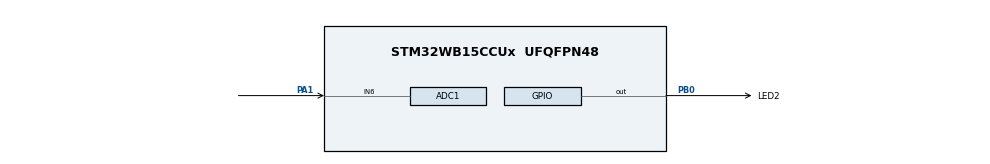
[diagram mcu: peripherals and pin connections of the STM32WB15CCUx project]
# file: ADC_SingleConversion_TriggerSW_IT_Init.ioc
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ADC1.Channel-0\#ChannelRegularConversion=ADC_CHANNEL_6
ADC1.ClockPrescaler=ADC_CLOCK_SYNC_PCLK_DIV4
ADC1.NbrOfConversionFlag=1
ADC1.Overrun=ADC_OVR_DATA_OVERWRITTEN
ADC1.Rank-0\#ChannelRegularConversion=1
ADC1.SamplingTime-0\#ChannelRegularConversion=ADC_SAMPLINGTIME_COMMON_1
ADC1.SamplingTimeCommon1=ADC_SAMPLETIME_79CYCLES_5
ADC1.SelectedChannel=ADC_CHANNEL_6
ADC1.master=1
Mcu.Family=STM32WB
Mcu.Name=STM32WB15CCUx
Mcu.Package=UFQFPN48
NVIC.ADC1_IRQn=true\:0\:0\:false\:false\:false\:true\:true
NVIC.PriorityGroup=NVIC_PRIORITYGROUP_4
PA1.Signal=ADCx_IN6
PB0.GPIO_Label=LED2
PB0.Signal=GPIO_Output
ProjectManager.HeapSize=0x200
ProjectManager.StackSize=0x400
ProjectManager.TargetToolchain=EWARM V8
RCC.AHB2CLKDivider=RCC_SYSCLK_DIV2
RCC.AHBFreq_Value=64000000
RCC.APB1Freq_Value=64000000
RCC.APB1TimFreq_Value=64000000
RCC.APB2Freq_Value=64000000
RCC.APB2TimFreq_Value=64000000
RCC.APB3Freq_Value=16000000
RCC.CortexFreq_Value=64000000
RCC.HCLKFreq_Value=64000000
RCC.HSE_VALUE=8000000
RCC.HSI_VALUE=16000000
RCC.LSE_VALUE=32768
RCC.PLLN=32
RCC.SYSCLKFreq_VALUE=64000000
RCC.SYSCLKSource=RCC_SYSCLKSOURCE_PLLCLK
RCC.VCOOutputFreq_Value=128000000
SH.ADCx_IN6.0=ADC1_IN6,IN6-Single-Ended
board=custom

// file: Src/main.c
/* USER CODE BEGIN Header */
/**
  ******************************************************************************
  * @file    Examples_LL/ADC/ADC_SingleConversion_TriggerSW_IT_Init/Src/main.c
  * @author  MCD Application Team
  * @brief   Use ADC to convert a single channel at each SW start.
  *          Conversion performed using programming model: interrupt
  *          This example is based on the STM32WBxx ADC LL API;
  *          Peripheral initialization done using LL unitary services functions.
  ******************************************************************************
  * @attention
  *
  * <h2><center>&copy; Copyright (c) 2019 STMicroelectronics.
  * All rights reserved.</center></h2>
  *
  * This software component is licensed by ST under BSD 3-Clause license,
  * the "License"; You may not use this file except in compliance with the
  * License. You may obtain a copy of the License at:
  *                        opensource.org/licenses/BSD-3-Clause
  *
  ******************************************************************************
  */
/* USER CODE END Header */
#include "main.h"

/* USER CODE BEGIN PD */

/* Definitions of ADC hardware constraints delays */
/* Note: Only ADC IP HW delays are defined in ADC LL driver driver,           */
/*       not timeout values:                                                  */
/*       Timeout values for ADC operations are dependent to device clock      */
/*       configuration (system clock versus ADC clock),                       */
/*       and therefore must be defined in user application.                   */
/*       Refer to @ref ADC_LL_EC_HW_DELAYS for description of ADC timeout     */
/*       values definition.                                                   */

  /* Timeout values for ADC operations. */
  /* (calibration, enable settling time, disable settling time, ...)          */
  /* Values defined to be higher than worst cases: low clock frequency,       */
  /* maximum prescalers.                                                      */
  /* Note: ADC channel configuration ready (ADC_CHANNEL_CONF_RDY_TIMEOUT_MS)  */
  /*       is added in CubeMx code section.                                   */
  /* Unit: ms                                                                 */
  #define ADC_CALIBRATION_TIMEOUT_MS       (   1UL)
  #define ADC_ENABLE_TIMEOUT_MS            (   1UL)
  #define ADC_DISABLE_TIMEOUT_MS           (   1UL)
  #define ADC_STOP_CONVERSION_TIMEOUT_MS   (   1UL)
  #define ADC_CONVERSION_TIMEOUT_MS        (4000UL)

  /* Delay between ADC end of calibration and ADC enable.                     */
  /* Delay estimation in CPU cycles: Case of ADC enable done                  */
  /* immediately after ADC calibration, ADC clock setting slow                */
  /* (LL_ADC_CLOCK_ASYNC_DIV32). Use a higher delay if ratio                  */
  /* (CPU clock / ADC clock) is above 32.                                     */
  #define ADC_DELAY_CALIB_ENABLE_CPU_CYCLES  (LL_ADC_DELAY_CALIB_ENABLE_ADC_CYCLES * 32)

/* Definitions of environment analog values */
  /* Value of analog reference voltage (Vref+), connected to analog voltage   */
  /* supply Vdda (unit: mV).                                                  */
  #define VDDA_APPLI                       (3300UL)

/* Definitions of data related to this example */
  /* Init variable out of expected ADC conversion data range */
  #define VAR_CONVERTED_DATA_INIT_VALUE    (__LL_ADC_DIGITAL_SCALE(LL_ADC_RESOLUTION_12B) + 1)

/* USER CODE END PD */

/* USER CODE BEGIN PV */

/* Variables for ADC conversion data */
__IO uint16_t uhADCxConvertedData = VAR_CONVERTED_DATA_INIT_VALUE; /* ADC group regular conversion data */

/* Variables for ADC conversion data computation to physical values */
uint16_t uhADCxConvertedData_Voltage_mVolt = 0;  /* Value of voltage calculated from ADC conversion data (unit: mV) */

/* Variable to report status of ADC group regular unitary conversion          */
/*  0: ADC group regular unitary conversion is not completed                  */
/*  1: ADC group regular unitary conversion is completed                      */
/*  2: ADC group regular unitary conversion has not been started yet          */
/*     (initial state)                                                        */
__IO uint8_t ubAdcGrpRegularUnitaryConvStatus = 2; /* Variable set into ADC interruption callback */

/* USER CODE END PV */

void SystemClock_Config(void);
static void MX_GPIO_Init(void);
static void MX_ADC1_Init(void);
/* USER CODE BEGIN PFP */

void ADC_Activate(void);
void LED_On(void);
void LED_Off(void);
void LED_Toggle(void);

/* USER CODE END PFP */

int main(void)
{

  /* MCU Configuration--------------------------------------------------------*/

  /* Reset of all peripherals, Initializes the Flash interface and the Systick. */

  NVIC_SetPriorityGrouping(NVIC_PRIORITYGROUP_4);

  /* System interrupt init*/

  /* Configure the system clock */
  SystemClock_Config();

  /* Initialize all configured peripherals */
  MX_GPIO_Init();
  MX_ADC1_Init();
  /* USER CODE BEGIN 2 */

  /* Activate ADC */
  /* Perform ADC activation procedure to make it ready to convert. */
  ADC_Activate();

  /* USER CODE END 2 */

  /* Infinite loop */
  /* USER CODE BEGIN WHILE */
  while (1)
  {
    /* Start ADC group regular conversion */
    /* Note: Hardware constraint (refer to description of the functions       */
    /*       below):                                                          */
    /*       On this STM32 series, setting of this feature is conditioned to  */
    /*       ADC state:                                                       */
    /*       ADC must be enabled without conversion on going on group regular,*/
    /*       without ADC disable command on going.                            */
    /* Note: In this example, all these checks are not necessary but are      */
    /*       implemented anyway to show the best practice usages              */
    /*       corresponding to reference manual procedure.                     */
    /*       Software can be optimized by removing some of these checks, if   */
    /*       they are not relevant considering previous settings and actions  */
    /*       in user application.                                             */
    if ((LL_ADC_IsEnabled(ADC1) == 1)               &&
        (LL_ADC_IsDisableOngoing(ADC1) == 0)        &&
        (LL_ADC_REG_IsConversionOngoing(ADC1) == 0)   )
    {
      LL_ADC_REG_StartConversion(ADC1);
    }
    else
    {
      /* Error: ADC conversion start could not be performed */
      Error_Handler();
    }

    /* For this example purpose, wait untill conversion is done */
    while (ubAdcGrpRegularUnitaryConvStatus != 1);

    /* Reset status variable of ADC group regular unitary conversion */
    ubAdcGrpRegularUnitaryConvStatus = 0;

    /* Toggle LED at each ADC conversion */
    LED_On();
    LL_mDelay(LED_BLINK_SLOW);
    LED_Off();
    LL_mDelay(LED_BLINK_SLOW);

    /* Note: ADC group regular conversions data are stored into array         */
    /*       "uhADCxConvertedData"                                            */
    /*       (for debug: see variable content into watch window).             */

    /* Note: ADC conversion data are computed to physical values              */
    /*       into array "uhADCxConvertedData_Voltage_mVolt" using             */
    /*       ADC LL driver helper macro "__LL_ADC_CALC_DATA_TO_VOLTAGE()"     */
    /*       (for debug: see variable content with debugger)                  */
    /*       in IRQ handler callback function.                                */

    /* USER CODE END WHILE */

  }
}

void SystemClock_Config(void)
{
  LL_FLASH_SetLatency(LL_FLASH_LATENCY_3);
  while(LL_FLASH_GetLatency() != LL_FLASH_LATENCY_3)
  {
  }

  /* HSI configuration and activation */
  LL_RCC_HSI_Enable();
  while(LL_RCC_HSI_IsReady() != 1)
  {
  }

  /* MSI configuration and activation */
  LL_RCC_MSI_Enable();
  while(LL_RCC_MSI_IsReady() != 1)
  {
  }

  /* Main PLL configuration and activation */
  LL_RCC_PLL_ConfigDomain_SYS(LL_RCC_PLLSOURCE_MSI, LL_RCC_PLLM_DIV_1, 32, LL_RCC_PLLR_DIV_2);
  LL_RCC_PLL_Enable();
  LL_RCC_PLL_EnableDomain_SYS();
  while(LL_RCC_PLL_IsReady() != 1)
  {
  }

  /* Sysclk activation on the main PLL */
  /* Set CPU1 prescaler*/
  LL_RCC_SetAHBPrescaler(LL_RCC_SYSCLK_DIV_1);

  /* Set CPU2 prescaler*/
  LL_C2_RCC_SetAHBPrescaler(LL_RCC_SYSCLK_DIV_2);

  LL_RCC_SetSysClkSource(LL_RCC_SYS_CLKSOURCE_PLL);
  while(LL_RCC_GetSysClkSource() != LL_RCC_SYS_CLKSOURCE_STATUS_PLL)
  {
  }

  /* Set AHB SHARED prescaler*/
  LL_RCC_SetAHB4Prescaler(LL_RCC_SYSCLK_DIV_1);

  /* Set APB1 prescaler*/
  LL_RCC_SetAPB1Prescaler(LL_RCC_APB1_DIV_1);

  /* Set APB2 prescaler*/
  LL_RCC_SetAPB2Prescaler(LL_RCC_APB2_DIV_1);

  LL_Init1msTick(64000000);

  /* Update CMSIS variable (which can be updated also through SystemCoreClockUpdate function) */
  LL_SetSystemCoreClock(64000000);
  LL_RCC_SetADCClockSource(LL_RCC_ADC_CLKSOURCE_HSI);
  LL_RCC_SetSMPSClockSource(LL_RCC_SMPS_CLKSOURCE_HSI);
  LL_RCC_SetSMPSPrescaler(LL_RCC_SMPS_DIV_1);
  LL_RCC_SetRFWKPClockSource(LL_RCC_RFWKP_CLKSOURCE_NONE);
}

static void MX_ADC1_Init(void)
{

  LL_ADC_CommonInitTypeDef ADC_CommonInitStruct = {0};
  LL_ADC_InitTypeDef ADC_InitStruct = {0};
  LL_ADC_REG_InitTypeDef ADC_REG_InitStruct = {0};

  LL_GPIO_InitTypeDef GPIO_InitStruct = {0};

  /* Peripheral clock enable */
  LL_APB2_GRP1_EnableClock(LL_APB2_GRP1_PERIPH_ADC);

  LL_AHB2_GRP1_EnableClock(LL_AHB2_GRP1_PERIPH_GPIOA);
  /**ADC1 GPIO Configuration
  PA1   ------> ADC1_IN6
  */
  GPIO_InitStruct.Pin = LL_GPIO_PIN_1;
  GPIO_InitStruct.Mode = LL_GPIO_MODE_ANALOG;
  GPIO_InitStruct.Pull = LL_GPIO_PULL_NO;
  LL_GPIO_Init(GPIOA, &GPIO_InitStruct);

  /* ADC1 interrupt Init */
  NVIC_SetPriority(ADC1_IRQn, NVIC_EncodePriority(NVIC_GetPriorityGrouping(),0, 0));
  NVIC_EnableIRQ(ADC1_IRQn);

  /** Common config
  */

  #define ADC_CHANNEL_CONF_RDY_TIMEOUT_MS ( 1U)
  #if (USE_TIMEOUT == 1)
  uint32_t Timeout ; /* Variable used for Timeout management */
  #endif /* USE_TIMEOUT */

  ADC_CommonInitStruct.CommonClock = LL_ADC_CLOCK_SYNC_PCLK_DIV4;
  LL_ADC_CommonInit(__LL_ADC_COMMON_INSTANCE(ADC1), &ADC_CommonInitStruct);
  ADC_InitStruct.Resolution = LL_ADC_RESOLUTION_12B;
  ADC_InitStruct.DataAlignment = LL_ADC_DATA_ALIGN_RIGHT;
  ADC_InitStruct.LowPowerMode = LL_ADC_LP_MODE_NONE;
  LL_ADC_Init(ADC1, &ADC_InitStruct);
  LL_ADC_REG_SetSequencerConfigurable(ADC1, LL_ADC_REG_SEQ_CONFIGURABLE);

  /* Poll for ADC channel configuration ready */
  #if (USE_TIMEOUT == 1)
  Timeout = ADC_CHANNEL_CONF_RDY_TIMEOUT_MS;
  #endif /* USE_TIMEOUT */
  while (LL_ADC_IsActiveFlag_CCRDY(ADC1) == 0)
  {
    #if (USE_TIMEOUT == 1)
    /* Check Systick counter flag to decrement the time-out value */
    if (LL_SYSTICK_IsActiveCounterFlag())
    {
      if(Timeout-- == 0)
      {
        Error_Handler();
      }
    }
    #endif /* USE_TIMEOUT */
  }
  /* Clear flag ADC channel configuration ready */
  LL_ADC_ClearFlag_CCRDY(ADC1);
  ADC_REG_InitStruct.TriggerSource = LL_ADC_REG_TRIG_SOFTWARE;
  ADC_REG_InitStruct.SequencerLength = LL_ADC_REG_SEQ_SCAN_DISABLE;
  ADC_REG_InitStruct.SequencerDiscont = LL_ADC_REG_SEQ_DISCONT_DISABLE;
  ADC_REG_InitStruct.ContinuousMode = LL_ADC_REG_CONV_SINGLE;
  ADC_REG_InitStruct.DMATransfer = LL_ADC_REG_DMA_TRANSFER_NONE;
  ADC_REG_InitStruct.Overrun = LL_ADC_REG_OVR_DATA_OVERWRITTEN;
  LL_ADC_REG_Init(ADC1, &ADC_REG_InitStruct);

  /* Enable ADC internal voltage regulator */
  LL_ADC_EnableInternalRegulator(ADC1);
  /* Delay for ADC internal voltage regulator stabilization. */
  /* Compute number of CPU cycles to wait for, from delay in us. */
  /* Note: Variable divided by 2 to compensate partially */
  /* CPU processing cycles (depends on compilation optimization). */
  /* Note: If system core clock frequency is below 200kHz, wait time */
  /* is only a few CPU processing cycles. */
  uint32_t wait_loop_index;
  wait_loop_index = ((LL_ADC_DELAY_INTERNAL_REGUL_STAB_US * (SystemCoreClock / (100000 * 2))) / 10);
  while(wait_loop_index != 0)
  {
    wait_loop_index--;
  }
  LL_ADC_SetSamplingTimeCommonChannels(ADC1, LL_ADC_SAMPLINGTIME_COMMON_1, LL_ADC_SAMPLINGTIME_79CYCLES_5);
  LL_ADC_SetSamplingTimeCommonChannels(ADC1, LL_ADC_SAMPLINGTIME_COMMON_2, LL_ADC_SAMPLINGTIME_1CYCLE_5);
  /** Configure Regular Channel
  */
  LL_ADC_REG_SetSequencerRanks(ADC1, LL_ADC_REG_RANK_1, LL_ADC_CHANNEL_6);

  /* Poll for ADC channel configuration ready */
  #if (USE_TIMEOUT == 1)
  Timeout = ADC_CHANNEL_CONF_RDY_TIMEOUT_MS;
  #endif /* USE_TIMEOUT */
  while (LL_ADC_IsActiveFlag_CCRDY(ADC1) == 0)
  {
    #if (USE_TIMEOUT == 1)
    /* Check Systick counter flag to decrement the time-out value */
    if (LL_SYSTICK_IsActiveCounterFlag())
    {
      if(Timeout-- == 0)
      {
        Error_Handler();
      }
    }
    #endif /* USE_TIMEOUT */
  }
  /* Clear flag ADC channel configuration ready */
  LL_ADC_ClearFlag_CCRDY(ADC1);
  LL_ADC_SetChannelSamplingTime(ADC1, LL_ADC_CHANNEL_6, LL_ADC_SAMPLINGTIME_COMMON_1);
  /* USER CODE BEGIN ADC1_Init 2 */

  /* Configuration of ADC interruptions */
  /* Enable interruption ADC group regular end of unitary conversion */
  LL_ADC_EnableIT_EOC(ADC1);

  /* Configuration of ADC interruptions */
  /* Enable interruption ADC group regular overrun */
  LL_ADC_EnableIT_OVR(ADC1);

  /* USER CODE END ADC1_Init 2 */

}

static void MX_GPIO_Init(void)
{
  LL_GPIO_InitTypeDef GPIO_InitStruct = {0};

  /* GPIO Ports Clock Enable */
  LL_AHB2_GRP1_EnableClock(LL_AHB2_GRP1_PERIPH_GPIOA);
  LL_AHB2_GRP1_EnableClock(LL_AHB2_GRP1_PERIPH_GPIOB);

  /**/
  LL_GPIO_ResetOutputPin(LED2_GPIO_Port, LED2_Pin);

  /**/
  GPIO_InitStruct.Pin = LED2_Pin;
  GPIO_InitStruct.Mode = LL_GPIO_MODE_OUTPUT;
  GPIO_InitStruct.Speed = LL_GPIO_SPEED_FREQ_LOW;
  GPIO_InitStruct.OutputType = LL_GPIO_OUTPUT_PUSHPULL;
  GPIO_InitStruct.Pull = LL_GPIO_PULL_NO;
  LL_GPIO_Init(LED2_GPIO_Port, &GPIO_InitStruct);

}

/* USER CODE BEGIN 4 */

/**
  * @brief  Perform ADC activation procedure to make it ready to convert
  *         (ADC instance: ADC1).
  * @param  None
  * @retval None
  */
void ADC_Activate(void)
{
  __IO uint32_t wait_loop_index = 0U;
  __IO uint32_t backup_setting_adc_dma_transfer = 0U;
  #if (USE_TIMEOUT == 1)
  uint32_t Timeout = 0U; /* Variable used for timeout management */
  #endif /* USE_TIMEOUT */

  /*## Operation on ADC hierarchical scope: ADC instance #####################*/

  /* Note: Hardware constraint (refer to description of the functions         */
  /*       below):                                                            */
  /*       On this STM32 series, setting of these features is conditioned to  */
  /*       ADC state:                                                         */
  /*       ADC must be disabled.                                              */
  /* Note: In this example, all these checks are not necessary but are        */
  /*       implemented anyway to show the best practice usages                */
  /*       corresponding to reference manual procedure.                       */
  /*       Software can be optimized by removing some of these checks, if     */
  /*       they are not relevant considering previous settings and actions    */
  /*       in user application.                                               */
  if (LL_ADC_IsEnabled(ADC1) == 0)
  {
    /* Enable ADC internal voltage regulator */
    LL_ADC_EnableInternalRegulator(ADC1);

    /* Delay for ADC internal voltage regulator stabilization.                */
    /* Compute number of CPU cycles to wait for, from delay in us.            */
    /* Note: Variable divided by 2 to compensate partially                    */
    /*       CPU processing cycles (depends on compilation optimization).     */
    /* Note: If system core clock frequency is below 200kHz, wait time        */
    /*       is only a few CPU processing cycles.                             */
    wait_loop_index = ((LL_ADC_DELAY_INTERNAL_REGUL_STAB_US * (SystemCoreClock / (100000 * 2))) / 10);
    while(wait_loop_index != 0)
    {
      wait_loop_index--;
    }

    /* Disable ADC DMA transfer request during calibration */
    /* Note: Specificity of this STM32 series: Calibration factor is           */
    /*       available in data register and also transferred by DMA.           */
    /*       To not insert ADC calibration factor among ADC conversion data   */
    /*       in DMA destination address, DMA transfer must be disabled during */
    /*       calibration.                                                     */
    backup_setting_adc_dma_transfer = LL_ADC_REG_GetDMATransfer(ADC1);
    LL_ADC_REG_SetDMATransfer(ADC1, LL_ADC_REG_DMA_TRANSFER_NONE);

    /* Run ADC self calibration */
    LL_ADC_StartCalibration(ADC1);

    /* Poll for ADC effectively calibrated */
    #if (USE_TIMEOUT == 1)
    Timeout = ADC_CALIBRATION_TIMEOUT_MS;
    #endif /* USE_TIMEOUT */

    while (LL_ADC_IsCalibrationOnGoing(ADC1) != 0)
    {
    #if (USE_TIMEOUT == 1)
      /* Check Systick counter flag to decrement the time-out value */
      if (LL_SYSTICK_IsActiveCounterFlag())
      {
        if(Timeout-- == 0)
        {
          /* Error: Time-out */
          Error_Handler();
        }
      }
    #endif /* USE_TIMEOUT */
    }

    /* Restore ADC DMA transfer request after calibration */
    LL_ADC_REG_SetDMATransfer(ADC1, backup_setting_adc_dma_transfer);

    /* Delay between ADC end of calibration and ADC enable.                   */
    /* Note: Variable divided by 2 to compensate partially                    */
    /*       CPU processing cycles (depends on compilation optimization).     */
    wait_loop_index = (ADC_DELAY_CALIB_ENABLE_CPU_CYCLES >> 1);
    while(wait_loop_index != 0)
    {
      wait_loop_index--;
    }

    /* Enable ADC */
    LL_ADC_Enable(ADC1);

    /* Poll for ADC ready to convert */
    #if (USE_TIMEOUT == 1)
    Timeout = ADC_ENABLE_TIMEOUT_MS;
    #endif /* USE_TIMEOUT */

    while (LL_ADC_IsActiveFlag_ADRDY(ADC1) == 0)
    {
    #if (USE_TIMEOUT == 1)
      /* Check Systick counter flag to decrement the time-out value */
      if (LL_SYSTICK_IsActiveCounterFlag())
      {
        if(Timeout-- == 0)
        {
          /* Error: Time-out */
          Error_Handler();
        }
      }
    #endif /* USE_TIMEOUT */
    }

    /* Note: ADC flag ADRDY is not cleared here to be able to check ADC       */
    /*       status afterwards.                                               */
    /*       This flag should be cleared at ADC Deactivation, before a new    */
    /*       ADC activation, using function "LL_ADC_ClearFlag_ADRDY()".       */
  }

  /*## Operation on ADC hierarchical scope: ADC group regular ################*/
  /* Note: No operation on ADC group regular performed here.                  */
  /*       ADC group regular conversions to be performed after this function  */
  /*       using function:                                                    */
  /*       "LL_ADC_REG_StartConversion();"                                    */

  /*## Operation on ADC hierarchical scope: ADC group injected ###############*/
  /* Note: Feature not available on this STM32 series */

}

/**
  * @brief  Turn-on LED2.
  * @param  None
  * @retval None
  */
void LED_On(void)
{
  /* Turn LED on */
  LL_GPIO_SetOutputPin(LED2_GPIO_Port, LED2_Pin);
}

/**
  * @brief  Turn-off LED2.
  * @param  None
  * @retval None
  */
void LED_Off(void)
{
  /* Turn LED off */
  LL_GPIO_ResetOutputPin(LED2_GPIO_Port, LED2_Pin);
}

/**
  * @brief  Toggle LED2.
  * @param  None
  * @retval None
  */
void LED_Toggle(void)
{
  /* Turn LED off */
  LL_GPIO_TogglePin(LED2_GPIO_Port, LED2_Pin);
}

/******************************************************************************/
/*   USER IRQ HANDLER TREATMENT                                               */
/******************************************************************************/

/**
  * @brief  ADC group regular end of unitary conversion interruption callback
  * @retval None
  */
void AdcGrpRegularUnitaryConvComplete_Callback()
{
  /* Retrieve ADC conversion data */
  uhADCxConvertedData = LL_ADC_REG_ReadConversionData32(ADC1);

  /* Computation of ADC conversions raw data to physical values           */
  /* using helper macro.                                                  */
  uhADCxConvertedData_Voltage_mVolt = __LL_ADC_CALC_DATA_TO_VOLTAGE(VDDA_APPLI, uhADCxConvertedData, LL_ADC_RESOLUTION_12B);

  /* Update status variable of ADC unitary conversion                     */
  ubAdcGrpRegularUnitaryConvStatus = 1;
}

/**
  * @brief  ADC group regular overrun interruption callback
  * @note   This function is executed when ADC group regular
  *         overrun error occurs.
  * @retval None
  */
void AdcGrpRegularOverrunError_Callback(void)
{
  /* Note: Disable ADC interruption that caused this error before entering in
           infinite loop below. */

  /* In case of error due to overrun: Disable ADC group regular overrun interruption */
  LL_ADC_DisableIT_OVR(ADC1);

  /* Error reporting */
  Error_Handler();
}

/* USER CODE END 4 */

void Error_Handler(void)
{
  /* USER CODE BEGIN Error_Handler_Debug */
  /* User can add his own implementation to report the HAL error return state */

  /* Turn on LED and remain in infinite loop */
  while (1)
  {
    LED_On();
  }
  /* USER CODE END Error_Handler_Debug */
}

/************************ (C) COPYRIGHT STMicroelectronics *****END OF FILE****/
